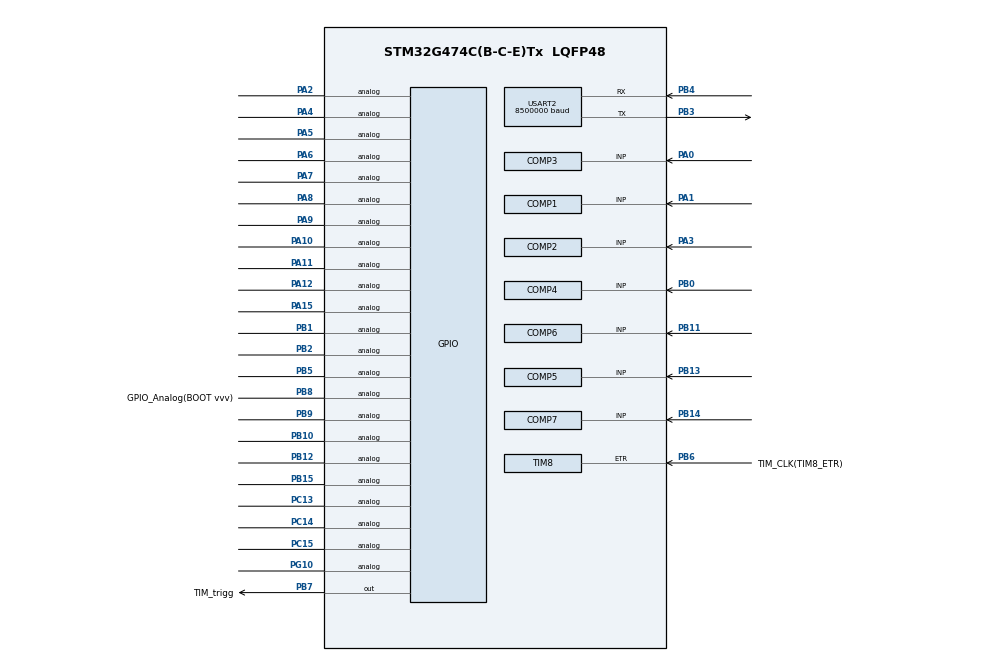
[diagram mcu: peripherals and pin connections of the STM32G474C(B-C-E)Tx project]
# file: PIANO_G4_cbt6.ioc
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COMP1.Hysteresis=COMP_HYSTERESIS_70MV
COMP1.TriggerMode=COMP_TRIGGERMODE_IT_FALLING
COMP2.Hysteresis=COMP_HYSTERESIS_70MV
COMP2.TriggerMode=COMP_TRIGGERMODE_IT_FALLING
COMP3.Hysteresis=COMP_HYSTERESIS_70MV
COMP3.TriggerMode=COMP_TRIGGERMODE_IT_FALLING
COMP4.Hysteresis=COMP_HYSTERESIS_70MV
COMP4.TriggerMode=COMP_TRIGGERMODE_IT_FALLING
COMP5.Hysteresis=COMP_HYSTERESIS_70MV
COMP5.TriggerMode=COMP_TRIGGERMODE_IT_FALLING
COMP6.Hysteresis=COMP_HYSTERESIS_70MV
COMP6.TriggerMode=COMP_TRIGGERMODE_IT_FALLING
COMP7.Hysteresis=COMP_HYSTERESIS_70MV
COMP7.TriggerMode=COMP_TRIGGERMODE_IT_FALLING
DAC1.DAC_Channel-DAC_OUT2_Int=DAC_CHANNEL_2
DAC3.DAC_Channel-DAC_OUT2_Int=DAC_CHANNEL_2
DAC4.DAC_Channel-DAC_OUT2_Int=DAC_CHANNEL_2
Dma.Request0=USART2_TX
Dma.USART2_TX.0.Direction=DMA_MEMORY_TO_PERIPH
Dma.USART2_TX.0.EventEnable=DISABLE
Dma.USART2_TX.0.Instance=DMA1_Channel1
Dma.USART2_TX.0.MemDataAlignment=DMA_MDATAALIGN_BYTE
Dma.USART2_TX.0.MemInc=DMA_MINC_ENABLE
Dma.USART2_TX.0.Mode=DMA_NORMAL
Dma.USART2_TX.0.PeriphDataAlignment=DMA_PDATAALIGN_BYTE
Dma.USART2_TX.0.PeriphInc=DMA_PINC_DISABLE
Dma.USART2_TX.0.Polarity=HAL_DMAMUX_REQ_GEN_RISING
Dma.USART2_TX.0.Priority=DMA_PRIORITY_LOW
Dma.USART2_TX.0.RequestNumber=1
Dma.USART2_TX.0.SignalID=NONE
Dma.USART2_TX.0.SyncEnable=DISABLE
Dma.USART2_TX.0.SyncPolarity=HAL_DMAMUX_SYNC_NO_EVENT
Dma.USART2_TX.0.SyncRequestNumber=1
Dma.USART2_TX.0.SyncSignalID=NONE
Mcu.Family=STM32G4
Mcu.Name=STM32G474C(B-C-E)Tx
Mcu.Package=LQFP48
NVIC.COMP1_2_3_IRQn=true\:2\:0\:true\:false\:true\:false\:true\:true
NVIC.COMP4_5_6_IRQn=true\:2\:0\:true\:false\:true\:false\:true\:true
NVIC.COMP7_IRQn=true\:2\:0\:true\:false\:true\:false\:true\:true
NVIC.DMA1_Channel1_IRQn=true\:3\:0\:true\:false\:true\:false\:true\:true
NVIC.PriorityGroup=NVIC_PRIORITYGROUP_4
NVIC.TIM8_CC_IRQn=true\:1\:0\:true\:false\:true\:true\:true\:true
NVIC.USART2_IRQn=true\:2\:0\:true\:false\:true\:true\:true\:true
PA0.Mode=INP
PA0.Signal=COMP3_INP
PA1.Mode=INP
PA1.Signal=COMP1_INP
PA10.Signal=GPIO_Analog
PA11.Signal=GPIO_Analog
PA12.Signal=GPIO_Analog
PA13.Mode=Serial_Wire
PA13.Signal=SYS_JTMS-SWDIO
PA14.Mode=Serial_Wire
PA14.Signal=SYS_JTCK-SWCLK
PA15.Signal=GPIO_Analog
PA2.Signal=GPIO_Analog
PA3.Mode=INP
PA3.Signal=COMP2_INP
PA4.Signal=GPIO_Analog
PA5.Signal=GPIO_Analog
PA6.Signal=GPIO_Analog
PA7.Signal=GPIO_Analog
PA8.Signal=GPIO_Analog
PA9.Signal=GPIO_Analog
PB0.Mode=INP
PB0.Signal=COMP4_INP
PB1.Signal=GPIO_Analog
PB10.Signal=GPIO_Analog
PB11.Mode=INP
PB11.Signal=COMP6_INP
PB12.Signal=GPIO_Analog
PB13.Mode=INP
PB13.Signal=COMP5_INP
PB14.Mode=INP
PB14.Signal=COMP7_INP
PB15.Signal=GPIO_Analog
PB2.Signal=GPIO_Analog
PB3.GPIO_ModeDefaultOD=GPIO_MODE_AF_PP
PB3.GPIO_PuPd=GPIO_NOPULL
PB3.GPIO_Speed=GPIO_SPEED_FREQ_MEDIUM
PB3.Mode=Multiprocessor_communication
PB3.Signal=USART2_TX
PB4.GPIO_ModeDefaultOD=GPIO_MODE_AF_PP
PB4.GPIO_Speed=GPIO_SPEED_FREQ_MEDIUM
PB4.Mode=Multiprocessor_communication
PB4.Signal=USART2_RX
PB5.Signal=GPIO_Analog
PB6.GPIO_Label=TIM_CLK(TIM8_ETR)
PB6.Signal=S_TIM8_ETR
PB7.GPIO_Label=TIM_trigg
PB7.GPIO_ModeDefaultOutputPP=GPIO_MODE_OUTPUT_OD
PB7.GPIO_PuPd=GPIO_NOPULL
PB7.Signal=GPIO_Output
PB8-BOOT0.GPIO_Label=GPIO_Analog(BOOT vvv)
PB8-BOOT0.Signal=GPIO_Analog
PB9.Signal=GPIO_Analog
PC13.Signal=GPIO_Analog
PC14-OSC32_IN.Signal=GPIO_Analog
PC15-OSC32_OUT.Signal=GPIO_Analog
PF0-OSC_IN.Mode=HSE-External-Oscillator
PF0-OSC_IN.Signal=RCC_OSC_IN
PF1-OSC_OUT.Mode=HSE-External-Oscillator
PF1-OSC_OUT.Signal=RCC_OSC_OUT
PG10-NRST.Signal=GPIO_Analog
ProjectManager.HeapSize=0x200
ProjectManager.StackSize=0x400
ProjectManager.TargetToolchain=CMake
RCC.ADC12Freq_Value=136000000
RCC.ADC345Freq_Value=136000000
RCC.AHBFreq_Value=136000000
RCC.APB1Freq_Value=136000000
RCC.APB1TimFreq_Value=136000000
RCC.APB2Freq_Value=136000000
RCC.APB2TimFreq_Value=136000000
RCC.CortexFreq_Value=136000000
RCC.EXTERNAL_CLOCK_VALUE=12288000
RCC.HCLKFreq_Value=136000000
RCC.HSE_VALUE=8000000
RCC.HSI48_VALUE=48000000
RCC.HSI_VALUE=16000000
RCC.LSE_VALUE=32768
RCC.PLLM=RCC_PLLM_DIV2
RCC.PLLN=68
RCC.PLLSourceVirtual=RCC_PLLSOURCE_HSE
RCC.PWR_Regulator_Voltage_Scale=PWR_REGULATOR_VOLTAGE_SCALE1_BOOST
RCC.SYSCLKFreq_VALUE=136000000
RCC.SYSCLKSource=RCC_SYSCLKSOURCE_PLLCLK
RCC.USBFreq_Value=136000000
RCC.VCOOutputFreq_Value=272000000
SH.S_TIM8_ETR.0=TIM8_ETR,TriggerSource_ETR
TIM2.Prescaler=13
TIM5.Prescaler=13599
TIM8.Channel-Output\ Compare3\ No\ Output=TIM_CHANNEL_3
TIM8.OCMode_3=TIM_OCMODE_PULSE_ON_COMPARE
TIM8.OCPolarity_3=TIM_OCPOLARITY_LOW
TIM8.PeriodNoDither=26
TIM8.PulseNoDither_3=3
TIM8.PulseWidth=1
TIM8.PulseWidthPrescaler=2
USART2.Address=7
USART2.AddressLength=UART_ADDRESS_DETECT_7B
USART2.BaudRate=8500000
USART2.OverSampling=UART_OVERSAMPLING_8
USART2.VirtualMode-Multiprocessor_communication=VM_ASYNC
USART2.WakeUpMethod=UART_WAKEUPMETHOD_ADDRESSMARK
USART2.WordLength=WORDLENGTH_9B
VP_COMP1_VS_DAC1OUT1.Mode=INM_DAC1OUT1
VP_COMP2_VS_DAC1OUT2.Mode=INM_DAC1OUT2
VP_COMP3_VS_DAC3OUT1.Mode=INM_DAC3OUT1
VP_COMP4_VS_DAC3OUT2.Mode=INM_DAC3OUT2
VP_COMP5_VS_DAC4OUT1.Mode=INM_DAC4OUT1
VP_COMP6_VS_DAC4OUT2.Mode=INM_DAC4OUT2
VP_COMP7_VS_DAC2OUT1.Mode=INM_DAC2OUT1
VP_DAC1_VS_DACI1.Mode=DAC_OUT1_Int
VP_DAC1_VS_DACI2.Mode=DAC_OUT2_Int
VP_DAC2_VS_DACI1.Mode=DAC_OUT1_Int
VP_DAC3_VS_DACI1.Mode=DAC_OUT1_Int
VP_DAC3_VS_DACI2.Mode=DAC_OUT2_Int
VP_DAC4_VS_DACI1.Mode=DAC_OUT1_Int
VP_DAC4_VS_DACI2.Mode=DAC_OUT2_Int
VP_SYS_VS_DBSignals.Mode=DisableDeadBatterySignals
VP_TIM2_VS_ClockSourceINT.Mode=Internal
VP_TIM5_VS_ClockSourceINT.Mode=Internal
VP_TIM6_VS_ClockSourceINT.Mode=Enable_Timer
VP_TIM8_VS_ControllerModeClock.Mode=Clock Mode
VP_TIM8_VS_no_output3.Mode=Output Compare3 No Output
board=custom

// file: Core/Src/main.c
/* USER CODE BEGIN Header */
/**
  ******************************************************************************
  * @file           : main.c
  * @brief          : Main program body
  ******************************************************************************
  * @attention
  *
  * Copyright (c) 2025 STMicroelectronics.
  * All rights reserved.
  *
  * This software is licensed under terms that can be found in the LICENSE file
  * in the root directory of this software component.
  * If no LICENSE file comes with this software, it is provided AS-IS.
  *
  ******************************************************************************
  */
/* USER CODE END Header */
#include "main.h"
#include "comp.h"
#include "dac.h"
#include "dma.h"
#include "tim.h"
#include "usart.h"
#include "gpio.h"

void SystemClock_Config(void);

int main(void)
{

  /* MCU Configuration--------------------------------------------------------*/

  /* Reset of all peripherals, Initializes the Flash interface and the Systick. */
  HAL_Init();

  /* Configure the system clock */
  SystemClock_Config();

  /* Initialize all configured peripherals */
  MX_GPIO_Init();
  MX_DMA_Init();
  MX_COMP1_Init();
  MX_COMP2_Init();
  MX_COMP3_Init();
  MX_COMP4_Init();
  MX_COMP5_Init();
  MX_COMP6_Init();
  MX_COMP7_Init();
  MX_TIM8_Init();
  MX_DAC1_Init();
  MX_DAC2_Init();
  MX_DAC3_Init();
  MX_DAC4_Init();
  MX_TIM2_Init();
  MX_TIM5_Init();
  MX_USART2_UART_Init();
  MX_TIM6_Init();
  /* USER CODE BEGIN 2 */
  g4();
  /* USER CODE END 2 */

  /* Infinite loop */
  while (1)
  {

  }
}

void SystemClock_Config(void)
{
  LL_FLASH_SetLatency(LL_FLASH_LATENCY_3);
  while(LL_FLASH_GetLatency() != LL_FLASH_LATENCY_3)
  {
  }
  LL_PWR_EnableRange1BoostMode();
  LL_RCC_HSE_Enable();
   /* Wait till HSE is ready */
  while(LL_RCC_HSE_IsReady() != 1)
  {
  }

  LL_RCC_PLL_ConfigDomain_SYS(LL_RCC_PLLSOURCE_HSE, LL_RCC_PLLM_DIV_2, 68, LL_RCC_PLLR_DIV_2);
  LL_RCC_PLL_EnableDomain_SYS();
  LL_RCC_PLL_Enable();
   /* Wait till PLL is ready */
  while(LL_RCC_PLL_IsReady() != 1)
  {
  }

  LL_RCC_SetSysClkSource(LL_RCC_SYS_CLKSOURCE_PLL);
  LL_RCC_SetAHBPrescaler(LL_RCC_SYSCLK_DIV_2);
   /* Wait till System clock is ready */
  while(LL_RCC_GetSysClkSource() != LL_RCC_SYS_CLKSOURCE_STATUS_PLL)
  {
  }

  /* Insure 1us transition state at intermediate medium speed clock*/
  for (__IO uint32_t i = (170 >> 1); i !=0; i--);

  /* Set AHB prescaler*/
  LL_RCC_SetAHBPrescaler(LL_RCC_SYSCLK_DIV_1);
  LL_RCC_SetAPB1Prescaler(LL_RCC_APB1_DIV_1);
  LL_RCC_SetAPB2Prescaler(LL_RCC_APB2_DIV_1);
  LL_SetSystemCoreClock(136000000);

   /* Update the time base */
  if (HAL_InitTick (TICK_INT_PRIORITY) != HAL_OK)
  {
    Error_Handler();
  }
}

void Error_Handler(void)
{
  __disable_irq();
  while (1)
  {
  }
}
